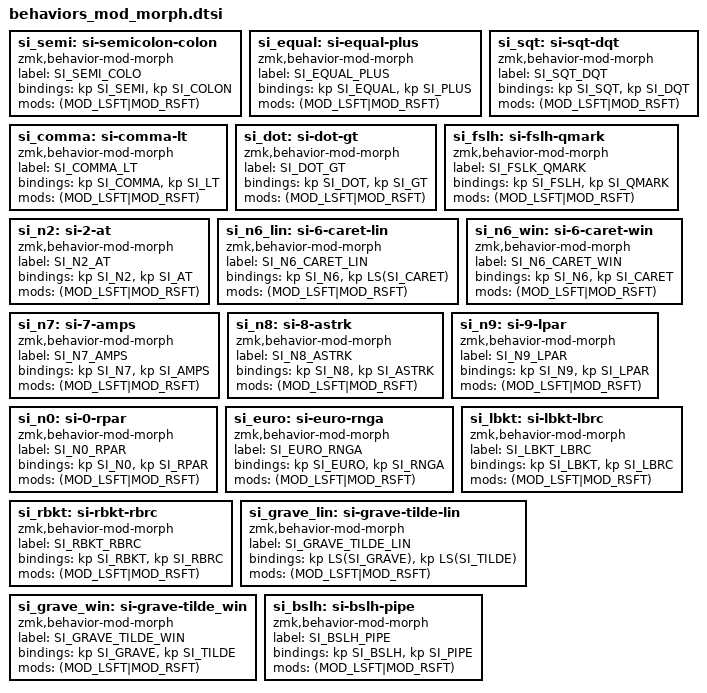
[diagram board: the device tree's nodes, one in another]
// Behaviors to support US like symbols when host layoust is SI

// ; :
si_semi: si-semicolon-colon {
  compatible = "zmk,behavior-mod-morph";
  label = "SI_SEMI_COLO";
  #binding-cells = <0>;
  bindings = <&kp SI_SEMI>, <&kp SI_COLON>;
  mods = <(MOD_LSFT|MOD_RSFT)>;
};

// = +
si_equal: si-equal-plus {
  compatible = "zmk,behavior-mod-morph";
  label = "SI_EQUAL_PLUS";
  #binding-cells = <0>;
  bindings = <&kp SI_EQUAL>, <&kp SI_PLUS>;
  mods = <(MOD_LSFT|MOD_RSFT)>;
};

// ' "
si_sqt: si-sqt-dqt {
  compatible = "zmk,behavior-mod-morph";
  label = "SI_SQT_DQT";
  #binding-cells = <0>;
  bindings = <&kp SI_SQT>, <&kp SI_DQT>;
  mods = <(MOD_LSFT|MOD_RSFT)>;
};

// , <
si_comma: si-comma-lt {
  compatible = "zmk,behavior-mod-morph";
  label = "SI_COMMA_LT";
  #binding-cells = <0>;
  bindings = <&kp SI_COMMA>, <&kp SI_LT>;
  mods = <(MOD_LSFT|MOD_RSFT)>;
};

// . >
si_dot: si-dot-gt {
  compatible = "zmk,behavior-mod-morph";
  label = "SI_DOT_GT";
  #binding-cells = <0>;
  bindings = <&kp SI_DOT>, <&kp SI_GT>;
  mods = <(MOD_LSFT|MOD_RSFT)>;
};

// / ?
si_fslh: si-fslh-qmark {
  compatible = "zmk,behavior-mod-morph";
  label = "SI_FSLK_QMARK";
  #binding-cells = <0>;
  bindings = <&kp SI_FSLH>, <&kp SI_QMARK>;
  mods = <(MOD_LSFT|MOD_RSFT)>;
};

// 2 @
si_n2: si-2-at {
  compatible = "zmk,behavior-mod-morph";
  label = "SI_N2_AT";
  #binding-cells = <0>;
  bindings = <&kp SI_N2>, <&kp SI_AT>;
  mods = <(MOD_LSFT|MOD_RSFT)>;
};

// 6 ^
si_n6_lin: si-6-caret-lin {
  compatible = "zmk,behavior-mod-morph";
  label = "SI_N6_CARET_LIN";
  #binding-cells = <0>;
  bindings = <&kp SI_N6>, <&kp LS(SI_CARET)>;
  mods = <(MOD_LSFT|MOD_RSFT)>;
};
si_n6_win: si-6-caret-win {
  compatible = "zmk,behavior-mod-morph";
  label = "SI_N6_CARET_WIN";
  #binding-cells = <0>;
  bindings = <&kp SI_N6>, <&kp SI_CARET>;
  mods = <(MOD_LSFT|MOD_RSFT)>;
};

// 7 &
si_n7: si-7-amps {
  compatible = "zmk,behavior-mod-morph";
  label = "SI_N7_AMPS";
  #binding-cells = <0>;
  bindings = <&kp SI_N7>, <&kp SI_AMPS>;
  mods = <(MOD_LSFT|MOD_RSFT)>;
};

// 8 *
si_n8: si-8-astrk {
  compatible = "zmk,behavior-mod-morph";
  label = "SI_N8_ASTRK";
  #binding-cells = <0>;
  bindings = <&kp SI_N8>, <&kp SI_ASTRK>;
  mods = <(MOD_LSFT|MOD_RSFT)>;
};

// 9 (
si_n9: si-9-lpar {
  compatible = "zmk,behavior-mod-morph";
  label = "SI_N9_LPAR";
  #binding-cells = <0>;
  bindings = <&kp SI_N9>, <&kp SI_LPAR>;
  mods = <(MOD_LSFT|MOD_RSFT)>;
};

// 0 )
si_n0: si-0-rpar {
  compatible = "zmk,behavior-mod-morph";
  label = "SI_N0_RPAR";
  #binding-cells = <0>;
  bindings = <&kp SI_N0>, <&kp SI_RPAR>;
  mods = <(MOD_LSFT|MOD_RSFT)>;
};

// € °
si_euro: si-euro-rnga {
  compatible = "zmk,behavior-mod-morph";
  label = "SI_EURO_RNGA";
  #binding-cells = <0>;
  bindings = <&kp SI_EURO>, <&kp SI_RNGA>;
  mods = <(MOD_LSFT|MOD_RSFT)>;
};

// [ {
si_lbkt: si-lbkt-lbrc {
  compatible = "zmk,behavior-mod-morph";
  label = "SI_LBKT_LBRC";
  #binding-cells = <0>;
  bindings = <&kp SI_LBKT>, <&kp SI_LBRC>;
  mods = <(MOD_LSFT|MOD_RSFT)>;
};

// ] }
si_rbkt: si-rbkt-rbrc {
  compatible = "zmk,behavior-mod-morph";
  label = "SI_RBKT_RBRC";
  #binding-cells = <0>;
  bindings = <&kp SI_RBKT>, <&kp SI_RBRC>;
  mods = <(MOD_LSFT|MOD_RSFT)>;
};

// ` ~
si_grave_lin: si-grave-tilde-lin {
  compatible = "zmk,behavior-mod-morph";
  label = "SI_GRAVE_TILDE_LIN";
  #binding-cells = <0>;
  bindings = <&kp LS(SI_GRAVE)>, <&kp LS(SI_TILDE)>;
  mods = <(MOD_LSFT|MOD_RSFT)>;
};
si_grave_win: si-grave-tilde_win {
  compatible = "zmk,behavior-mod-morph";
  label = "SI_GRAVE_TILDE_WIN";
  #binding-cells = <0>;
  bindings = <&kp SI_GRAVE>, <&kp SI_TILDE>;
  mods = <(MOD_LSFT|MOD_RSFT)>;
};

// \ |
si_bslh: si-bslh-pipe {
  compatible = "zmk,behavior-mod-morph";
  label = "SI_BSLH_PIPE";
  #binding-cells = <0>;
  bindings = <&kp SI_BSLH>, <&kp SI_PIPE>;
  mods = <(MOD_LSFT|MOD_RSFT)>;
};
